# JTAG register map
Vendor: litex
Registers are 32-bit, read-write, reset 0x0 unless marked. A register's access mark holds for its fields unless they carry their own. Offsets are from the block's base; [hi:lo] are bit positions.

## INFO
Base 0xF0008000
0x00 DNA_ID1 ro — Bits 32-56 of `INFO_DNA_ID`.
  [31:0] dna_id
0x04 DNA_ID0 ro — Bits 0-31 of `INFO_DNA_ID`.
  [31:0] dna_id
0x08 GIT_MAJOR ro — Major git tag version. For example, this firmware was built from git tag ``v0.0.0``, so this value is ``0``.
  [7:0] git_major
0x0C GIT_MINOR ro — Minor git tag version. For example, this firmware was built from git tag ``v0.0.0``, so this value is ``0``.
  [7:0] git_minor
0x10 GIT_REVISION ro — Revision git tag version. For example, this firmware was built from git tag ``v0.0.0``, so this value is ``0``.
  [7:0] git_revision
0x14 GIT_GITREV ro — First 32-bits of the git revision. This documentation was built from git rev ``00000000``, so this value is 0, which should be enough to check out the exact git version used to build this firmware.
0x18 GIT_GITEXTRA ro — The number of additional commits beyond the git tag. For example, if this value is ``1``, then the repository this was built from has one additional commit beyond the tag indicated in `MAJOR`, `MINOR`, and `REVISION`.
  [9:0] git_gitextra
0x1C GIT_DIRTY ro
  [0] dirty — Set to ``1`` if this device was built from a git repo with uncommitted modifications.
0x20 PLATFORM_PLATFORM1 ro — Bits 32-63 of `INFO_PLATFORM_PLATFORM`.
  [31:0] platform_platform
0x24 PLATFORM_PLATFORM0 ro — Bits 0-31 of `INFO_PLATFORM_PLATFORM`.
  [31:0] platform_platform
0x28 PLATFORM_TARGET1 ro — Bits 32-63 of `INFO_PLATFORM_TARGET`.
  [31:0] platform_target
0x2C PLATFORM_TARGET0 ro — Bits 0-31 of `INFO_PLATFORM_TARGET`.
  [31:0] platform_target
0x30 XADC_TEMPERATURE ro — Raw Temperature value from XADC. Temperature (°C) = ``Value`` x 503.975 / 4096 - 273.15.
  [11:0] xadc_temperature
0x34 XADC_VCCINT ro — Raw VCCINT value from XADC. VCCINT (V) = ``Value`` x 3 / 4096.
  [11:0] xadc_vccint
0x38 XADC_VCCAUX ro — Raw VCCAUX value from XADC. VCCAUX (V) = ``Value`` x 3 / 4096.
  [11:0] xadc_vccaux
0x3C XADC_VCCBRAM ro — Raw VCCBRAM value from XADC. VCCBRAM (V) = ``Value`` x 3 / 4096.
  [11:0] xadc_vccbram
0x40 XADC_EOC ro — End of Convertion Status, ``1``: Convertion Done.
  [0] xadc_eoc
0x44 XADC_EOS ro — End of Sequence Status, ``1``: Sequence Done.
  [0] xadc_eos
0x48 XADC_DRP_ENABLE
  [0] xadc_drp_enable
0x4C XADC_DRP_READ
  [0] xadc_drp_read
0x50 XADC_DRP_WRITE
  [0] xadc_drp_write
0x54 XADC_DRP_DRDY ro
  [0] xadc_drp_drdy
0x58 XADC_DRP_ADR
  [6:0] xadc_drp_adr
0x5C XADC_DRP_DAT_W
  [15:0] xadc_drp_dat_w
0x60 XADC_DRP_DAT_R ro
  [15:0] xadc_drp_dat_r

## SRAM_EXT
Base 0xF0009000
0x00 CONFIG_STATUS ro
  [31:0] mode — The current configuration mode of the SRAM
0x04 READ_CONFIG
  [0] trigger — Writing to this bit triggers the SRAM mode status read update

## MEMLCD
Base 0xF000A000
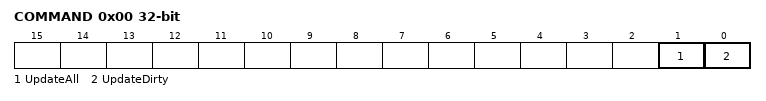
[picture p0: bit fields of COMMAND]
0x00 COMMAND
  [1] UpdateAll — Update full screen regardless of tag state
  [0] UpdateDirty — Write a ``1`` to flush dirty lines to the LCD
0x04 BUSY ro — A ``1`` indicates that the block is currently updating the LCD
  [0] busy
0x08 PRESCALER reset 0x63 — Prescaler value. LCD clock is module ``(clock / (prescaler+1))``. Reset value: ``99``, so for a default sysclk of 100MHz this yields an LCD ``SCLK`` of 1MHz
  [7:0] prescaler
0x0C EV_STATUS
  [0] status
0x10 EV_PENDING
  [0] pending
0x14 EV_ENABLE
  [0] enable

## COM
Base 0xF000B000
0x00 TX — Tx data, for COPI. Note: 32-bit CSRs are required for this block to work!
  [15:0] tx
0x04 RX ro — Rx data, from CIPO
  [15:0] rx
0x08 CONTROL
  [0] intena — Enable interrupt on transaction finished
0x0C STATUS ro
  [0] tip — Set when transaction is in progress
0x10 EV_STATUS
  [0] status
0x14 EV_PENDING
  [0] pending
0x18 EV_ENABLE
  [0] enable

## I2C
Base 0xF000C000
0x00 PRESCALE reset 0xFFFF — Prescaler value. Set to (module clock / (5 * I2C freq) - 1). Example: if module clock is equal to sysclk; syclk is 100MHz; and I2C freq is 100kHz, then prescaler is (100MHz / (5 * 100kHz) - 1) = 199. Reset value: 0xFFFF
  [15:0] prescale
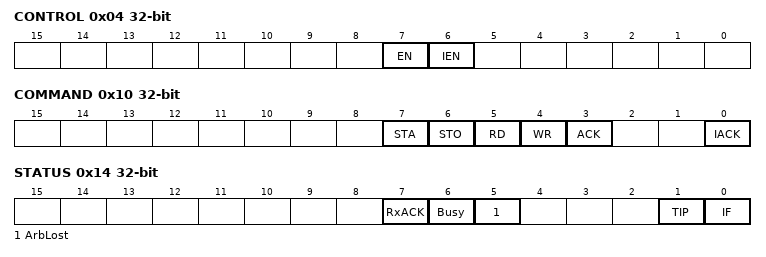
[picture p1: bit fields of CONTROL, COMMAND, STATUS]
0x04 CONTROL
  [7] EN — When set to `1`, the core is enabled.
  [6] IEN — When set to `1`, interrupts are enabled.
0x08 TXR — Next byte to transmit to slave devices. LSB indicates R/W during address phases, `1` for reading from slaves, `0` for writing to slaves
  [7:0] txr
0x0C RXR ro — Data being read from slaved devices
  [7:0] rxr
0x10 COMMAND
  [7] STA — generate (repeated) start condition
  [6] STO — generate stop condition
  [5] RD — read from slave
  [4] WR — write to slave
  [3] ACK — when a receiver, sent ack (`ACK=0`) or nack (`ACK=1`)
  [0] IACK — Interrupt acknowledge; when set, clears a pending interrupt
0x14 STATUS ro
  [7] RxACK — Received acknowledge from slave. 1 = no ack received, 0 = ack received
  [6] Busy — I2C block is busy processing the latest command
  [5] ArbLost — Set when arbitration for the bus is lost
  [1] TIP — transfer in progress
  [0] IF — Interrupt flag, This bit is set when an interrupt is pending, which will cause a processor interrupt request if the IEN bit is set. The Interrupt Flag is set upon the completion of one byte of data transfer.
0x18 EV_STATUS
  [0] status
0x1C EV_PENDING
  [0] pending
0x20 EV_ENABLE
  [0] enable
